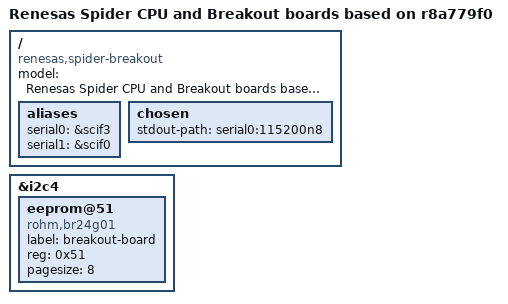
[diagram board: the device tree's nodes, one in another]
// SPDX-License-Identifier: (GPL-2.0 or MIT)
/*
 * Device Tree Source for the Spider CPU and BreakOut boards
 *
 * Copyright (C) 2021 Renesas Electronics Corp.
 */

/dts-v1/;
#include "r8a779f0-spider-cpu.dtsi"
#include "r8a779f0-spider-ethernet.dtsi"

/ {
	model = "Renesas Spider CPU and Breakout boards based on r8a779f0";
	compatible = "renesas,spider-breakout", "renesas,spider-cpu", "renesas,r8a779f0";

	aliases {
		serial0 = &scif3;
		serial1 = &scif0;
	};

	chosen {
		stdout-path = "serial0:115200n8";
	};
};

&i2c4 {
	eeprom@51 {
		compatible = "rohm,br24g01", "atmel,24c01";
		label = "breakout-board";
		reg = <0x51>;
		pagesize = <8>;
	};
};
